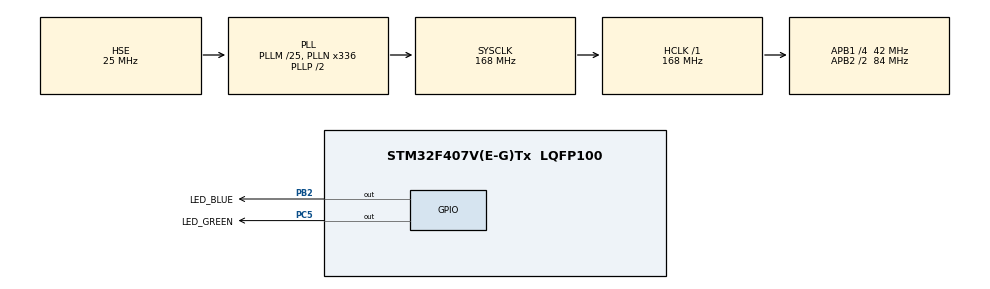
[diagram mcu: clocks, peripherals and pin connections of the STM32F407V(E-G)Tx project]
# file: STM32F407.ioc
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Mcu.Family=STM32F4
Mcu.Name=STM32F407V(E-G)Tx
Mcu.Package=LQFP100
NVIC.PriorityGroup=NVIC_PRIORITYGROUP_4
PA13.Mode=Serial_Wire
PA13.Signal=SYS_JTMS-SWDIO
PA14.Mode=Serial_Wire
PA14.Signal=SYS_JTCK-SWCLK
PB2.GPIO_Label=LED_BLUE
PB2.Signal=GPIO_Output
PC5.GPIO_Label=LED_GREEN
PC5.Signal=GPIO_Output
PH0-OSC_IN.Mode=HSE-External-Oscillator
PH0-OSC_IN.Signal=RCC_OSC_IN
PH1-OSC_OUT.Mode=HSE-External-Oscillator
PH1-OSC_OUT.Signal=RCC_OSC_OUT
ProjectManager.HeapSize=0x200
ProjectManager.StackSize=0x1000
ProjectManager.TargetToolchain=MDK-ARM V5.32
RCC.48MHZClocksFreq_Value=84000000
RCC.AHBFreq_Value=168000000
RCC.APB1CLKDivider=RCC_HCLK_DIV4
RCC.APB1Freq_Value=42000000
RCC.APB1TimFreq_Value=84000000
RCC.APB2CLKDivider=RCC_HCLK_DIV2
RCC.APB2Freq_Value=84000000
RCC.APB2TimFreq_Value=168000000
RCC.CortexFreq_Value=168000000
RCC.HCLKFreq_Value=168000000
RCC.HSE_VALUE=25000000
RCC.HSI_VALUE=16000000
RCC.LSE_VALUE=32768
RCC.PLLM=25
RCC.PLLN=336
RCC.PLLSourceVirtual=RCC_PLLSOURCE_HSE
RCC.SYSCLKFreq_VALUE=168000000
RCC.SYSCLKSource=RCC_SYSCLKSOURCE_PLLCLK
RCC.VCOOutputFreq_Value=336000000
board=custom

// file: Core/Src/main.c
/* USER CODE BEGIN Header */
/***********************************************************************************************************************************
 ** 【代码编写】  魔女开发板团队
 ** 【淘    宝】  魔女开发板       https://demoboard.taobao.com
 ***********************************************************************************************************************************
 ** 【实验名称】  STM32F407 GPIO 输出 —— LED 无阻塞闪烁
 **
 ** 【适用平台】  STM32F407 + keil5 + HAL库
 **
 ** 【 CubeMX 】  1- 开启外部高速晶振 HSE，系统时钟配置为 168MHz；
 **               2- 将 PB2、PC5 引脚配置为 GPIO 推挽输出模式；
 **               3- 无需开启其他外设，仅配置基础 GPIO 即可；
 **
 ** 【功能说明】  本工程实现 GPIO 无阻塞闪烁控制：
 **               1- 采用 HAL_GetTick() 计时，不阻塞主循环；
 **               2- 蓝灯(PB2)、绿灯(PC5) 500ms 同步翻转闪烁；
 **               3- 上电初始化：蓝灯亮、绿灯灭；
 **               4- 适合学习多任务、定时、非阻塞编程思想；
 **
 ** 【代码使用】  1- 编译下载后，LED 自动 500ms 闪烁一次；
 **               2- 可修改判断时间值（500）调整闪烁速度；
 **               3- 主循环不被卡住，可同时运行其他任务；
 **
 ** 【划 重 点】  1- 本开发板 LED = 低电平点亮、高电平熄灭；
 **               2- 无阻塞定时 = 不使用 HAL_Delay，不卡住 CPU；
 **               3- HAL_GPIO_TogglePin() = 自动翻转引脚电平；
 **               4- 静态变量 static 用于保存上一次的计时值；
 **
 *******************************************************************************/
/* USER CODE END Header */
#include "main.h"
#include "gpio.h"

void SystemClock_Config(void);

int main(void)
{
    /* USER CODE BEGIN 1 */

    /* 说明：
     * 1. 不要删除CubeMX生成的注释行（形如 USER CODE BEGIN/END），这些注释用于代码重新生成时的定位
     * 2. 所有用户自定义代码必须写在对应的BEGIN与END注释行之间，否则重新生成时会被覆盖
     * 3. 主要初始化函数说明：
     *    - HAL_Init()            初始化HAL库，配置中断优先级、系统时基等
     *    - SystemClock_Config()  配置系统时钟
     *    - MX_GPIO_Init()        初始化GPIO引脚（仅包含推挽输出、中断触发等配置）
     *    - 外设功能引脚（如UART、SPI等）的初始化在各自的功能文件中
     */

    /* USER CODE END 1 */

    /* MCU Configuration--------------------------------------------------------*/

    /* Reset of all peripherals, Initializes the Flash interface and the Systick. */
    HAL_Init();

    /* Configure the system clock */
    SystemClock_Config();

    /* Initialize all configured peripherals */
    MX_GPIO_Init();
    /* USER CODE BEGIN 2 */

    HAL_GPIO_WritePin(LED_BLUE_GPIO_Port, LED_BLUE_Pin, GPIO_PIN_RESET);    // 蓝灯，置低电平，点亮
    HAL_GPIO_WritePin(LED_GREEN_GPIO_Port, LED_GREEN_Pin, GPIO_PIN_SET);    // 绿灯，置高电平，熄灭

    /* USER CODE END 2 */

    /* Infinite loop */
    while (1)
    {

        /* USER CODE BEGIN 3 */

        /** ms延时;  注意：CubeMX生成的HAL_Delay()函数，为了避免无效操作，函数内部会对参数进行+1操作 **/
        HAL_Delay(1 - 1);

        /** 每500ms执行一次的任务 **/
        static uint32_t lastTime_500ms = 0;                          // 定义静态变量，用于记录上次执行这个任务的时间点(单位：毫秒)
        if (HAL_GetTick() - lastTime_500ms >= 500)                   // 检查当前时间距离上次执行是否已经过了500毫秒; HAL_GetTick()是获取启动后经过的毫秒数
        {
            HAL_GPIO_TogglePin(LED_BLUE_GPIO_Port, LED_BLUE_Pin);    // 控制蓝色LED引脚电平翻转(PB2); 规律地闪烁LED，方便外部观察系统是否正常运行
            HAL_GPIO_TogglePin(LED_GREEN_GPIO_Port, LED_GREEN_Pin);  // 控制绿色LED引脚电平翻转(PC5); 规律地闪烁LED，方便外部观察系统是否正常运行
            lastTime_500ms =   HAL_GetTick();                        // 记录当前时间，作为新的基准点，为下一次判断做准备
        }

    }

    /* USER CODE END 3 */
}

void SystemClock_Config(void)
{
    RCC_OscInitTypeDef RCC_OscInitStruct = {0};
    RCC_ClkInitTypeDef RCC_ClkInitStruct = {0};

    /** Configure the main internal regulator output voltage
    */
    __HAL_RCC_PWR_CLK_ENABLE();
    __HAL_PWR_VOLTAGESCALING_CONFIG(PWR_REGULATOR_VOLTAGE_SCALE1);

    /** Initializes the RCC Oscillators according to the specified parameters
    * in the RCC_OscInitTypeDef structure.
    */
    RCC_OscInitStruct.OscillatorType = RCC_OSCILLATORTYPE_HSE;
    RCC_OscInitStruct.HSEState = RCC_HSE_ON;
    RCC_OscInitStruct.PLL.PLLState = RCC_PLL_ON;
    RCC_OscInitStruct.PLL.PLLSource = RCC_PLLSOURCE_HSE;
    RCC_OscInitStruct.PLL.PLLM = 25;
    RCC_OscInitStruct.PLL.PLLN = 336;
    RCC_OscInitStruct.PLL.PLLP = RCC_PLLP_DIV2;
    RCC_OscInitStruct.PLL.PLLQ = 4;
    if (HAL_RCC_OscConfig(&RCC_OscInitStruct) != HAL_OK)
    {
        Error_Handler();
    }

    /** Initializes the CPU, AHB and APB buses clocks
    */
    RCC_ClkInitStruct.ClockType = RCC_CLOCKTYPE_HCLK | RCC_CLOCKTYPE_SYSCLK
                                  | RCC_CLOCKTYPE_PCLK1 | RCC_CLOCKTYPE_PCLK2;
    RCC_ClkInitStruct.SYSCLKSource = RCC_SYSCLKSOURCE_PLLCLK;
    RCC_ClkInitStruct.AHBCLKDivider = RCC_SYSCLK_DIV1;
    RCC_ClkInitStruct.APB1CLKDivider = RCC_HCLK_DIV4;
    RCC_ClkInitStruct.APB2CLKDivider = RCC_HCLK_DIV2;

    if (HAL_RCC_ClockConfig(&RCC_ClkInitStruct, FLASH_LATENCY_5) != HAL_OK)
    {
        Error_Handler();
    }
}

void Error_Handler(void)
{
    __disable_irq();
    while (1)
    {
    }
}
